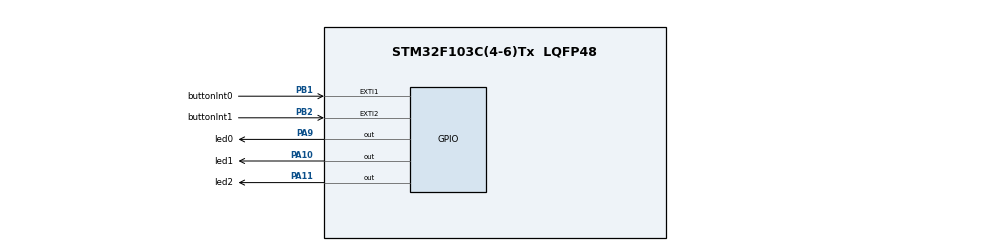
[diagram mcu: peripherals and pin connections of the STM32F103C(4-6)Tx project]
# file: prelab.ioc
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Mcu.Family=STM32F1
Mcu.Name=STM32F103C(4-6)Tx
Mcu.Package=LQFP48
NVIC.EXTI1_IRQn=true\:2\:0\:true\:false\:true\:true\:true\:true
NVIC.EXTI2_IRQn=true\:2\:0\:true\:false\:true\:true\:true\:true
NVIC.PriorityGroup=NVIC_PRIORITYGROUP_4
PA10.GPIO_Label=led1
PA10.Signal=GPIO_Output
PA11.GPIO_Label=led2
PA11.Signal=GPIO_Output
PA9.GPIO_Label=led0
PA9.Signal=GPIO_Output
PB1.GPIO_Label=buttonInt0
PB1.Signal=GPXTI1
PB2.GPIO_Label=buttonInt1
PB2.Signal=GPXTI2
ProjectManager.HeapSize=0x200
ProjectManager.StackSize=0x400
ProjectManager.TargetToolchain=MDK-ARM V5.32
RCC.APB1Freq_Value=8000000
RCC.APB2Freq_Value=8000000
VP_SYS_VS_ND.Mode=No_Debug
board=custom

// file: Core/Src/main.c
/* USER CODE BEGIN Header */
/**
  ******************************************************************************
  * @file           : main.c
  * @brief          : Main program body
  ******************************************************************************
  * @attention
  *
  * Copyright (c) 2025 STMicroelectronics.
  * All rights reserved.
  *
  * This software is licensed under terms that can be found in the LICENSE file
  * in the root directory of this software component.
  * If no LICENSE file comes with this software, it is provided AS-IS.
  *
  ******************************************************************************
  */
/* USER CODE END Header */
#include "main.h"

/* USER CODE BEGIN PV */
uint16_t counter = 0;
/* USER CODE END PV */

void SystemClock_Config(void);
static void MX_GPIO_Init(void);

/* USER CODE BEGIN 0 */
void update_leds(uint16_t value){

	GPIO_PinState led0_value, led1_value, led2_value;
	led0_value = (value & (uint16_t) 1) ? GPIO_PIN_SET : GPIO_PIN_RESET;
	led1_value = (value & (uint16_t) 2) ? GPIO_PIN_SET : GPIO_PIN_RESET;
	led2_value = (value & (uint16_t) 4) ? GPIO_PIN_SET : GPIO_PIN_RESET;

	HAL_GPIO_WritePin(led0_GPIO_Port,led0_Pin,led0_value);
	HAL_GPIO_WritePin(led1_GPIO_Port,led1_Pin,led1_value);
	HAL_GPIO_WritePin(led2_GPIO_Port,led2_Pin,led2_value);

}
/* USER CODE END 0 */

int main(void)
{

  /* MCU Configuration--------------------------------------------------------*/

  /* Reset of all peripherals, Initializes the Flash interface and the Systick. */
  HAL_Init();

  /* Configure the system clock */
  SystemClock_Config();

  /* Initialize all configured peripherals */
  MX_GPIO_Init();

  /* Infinite loop */
  while (1)
  {

  }
}

void SystemClock_Config(void)
{
  RCC_OscInitTypeDef RCC_OscInitStruct = {0};
  RCC_ClkInitTypeDef RCC_ClkInitStruct = {0};

  /** Initializes the RCC Oscillators according to the specified parameters
  * in the RCC_OscInitTypeDef structure.
  */
  RCC_OscInitStruct.OscillatorType = RCC_OSCILLATORTYPE_HSI;
  RCC_OscInitStruct.HSIState = RCC_HSI_ON;
  RCC_OscInitStruct.HSICalibrationValue = RCC_HSICALIBRATION_DEFAULT;
  RCC_OscInitStruct.PLL.PLLState = RCC_PLL_NONE;
  if (HAL_RCC_OscConfig(&RCC_OscInitStruct) != HAL_OK)
  {
    Error_Handler();
  }

  /** Initializes the CPU, AHB and APB buses clocks
  */
  RCC_ClkInitStruct.ClockType = RCC_CLOCKTYPE_HCLK|RCC_CLOCKTYPE_SYSCLK
                              |RCC_CLOCKTYPE_PCLK1|RCC_CLOCKTYPE_PCLK2;
  RCC_ClkInitStruct.SYSCLKSource = RCC_SYSCLKSOURCE_HSI;
  RCC_ClkInitStruct.AHBCLKDivider = RCC_SYSCLK_DIV1;
  RCC_ClkInitStruct.APB1CLKDivider = RCC_HCLK_DIV1;
  RCC_ClkInitStruct.APB2CLKDivider = RCC_HCLK_DIV1;

  if (HAL_RCC_ClockConfig(&RCC_ClkInitStruct, FLASH_LATENCY_0) != HAL_OK)
  {
    Error_Handler();
  }
}

static void MX_GPIO_Init(void)
{
  GPIO_InitTypeDef GPIO_InitStruct = {0};

  /* GPIO Ports Clock Enable */
  __HAL_RCC_GPIOB_CLK_ENABLE();
  __HAL_RCC_GPIOA_CLK_ENABLE();

  /*Configure GPIO pin Output Level */
  HAL_GPIO_WritePin(GPIOA, led0_Pin|led1_Pin|led2_Pin, GPIO_PIN_RESET);

  /*Configure GPIO pins : buttonInt0_Pin buttonInt1_Pin */
  GPIO_InitStruct.Pin = buttonInt0_Pin|buttonInt1_Pin;
  GPIO_InitStruct.Mode = GPIO_MODE_IT_RISING;
  GPIO_InitStruct.Pull = GPIO_NOPULL;
  HAL_GPIO_Init(GPIOB, &GPIO_InitStruct);

  /*Configure GPIO pins : led0_Pin led1_Pin led2_Pin */
  GPIO_InitStruct.Pin = led0_Pin|led1_Pin|led2_Pin;
  GPIO_InitStruct.Mode = GPIO_MODE_OUTPUT_PP;
  GPIO_InitStruct.Pull = GPIO_NOPULL;
  GPIO_InitStruct.Speed = GPIO_SPEED_FREQ_LOW;
  HAL_GPIO_Init(GPIOA, &GPIO_InitStruct);

  /* EXTI interrupt init*/
  HAL_NVIC_SetPriority(EXTI1_IRQn, 2, 0);
  HAL_NVIC_EnableIRQ(EXTI1_IRQn);

  HAL_NVIC_SetPriority(EXTI2_IRQn, 2, 0);
  HAL_NVIC_EnableIRQ(EXTI2_IRQn);

}

void Error_Handler(void)
{
  __disable_irq();
  while (1)
  {
  }
}
